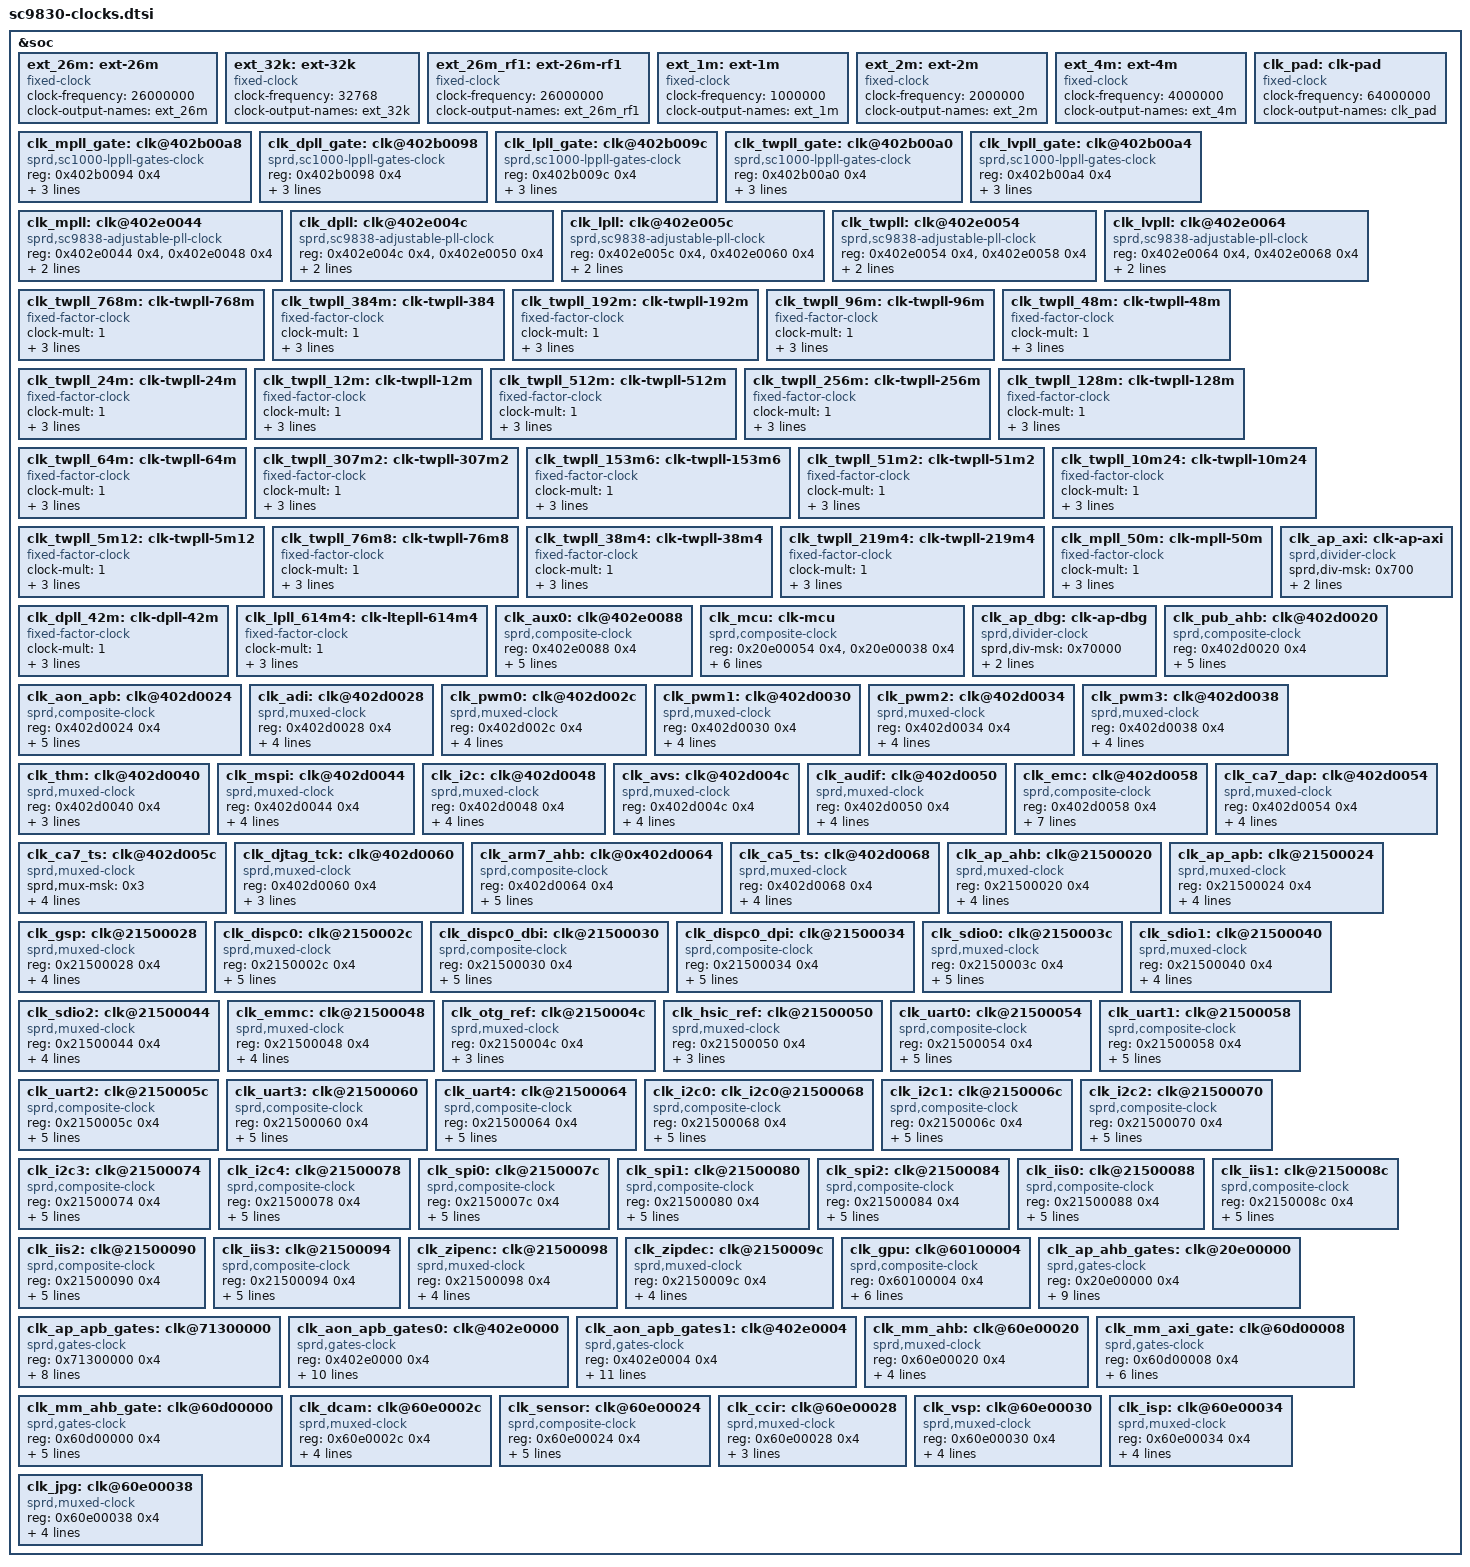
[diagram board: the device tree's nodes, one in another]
/*
 * Spreadtrum SC9830 SoC DTS file
 *
 * Copyright (C) 2015, Spreadtrum Communications Inc.
 *
 * This file is licensed under a dual GPLv2 or X11 license.
 */
&soc {
	ext_26m: ext-26m {
		compatible = "fixed-clock";
		#clock-cells = <0>;
		clock-frequency = <26000000>;
		clock-output-names = "ext_26m";
	};

	ext_32k: ext-32k {
		compatible = "fixed-clock";
		#clock-cells = <0>;
		clock-frequency = <32768>;
		clock-output-names = "ext_32k";
	};

	ext_26m_rf1: ext-26m-rf1 {
		compatible = "fixed-clock";
		#clock-cells = <0>;
		clock-frequency = <26000000>;
		clock-output-names = "ext_26m_rf1";
	};

	ext_1m: ext-1m {
		compatible = "fixed-clock";
		#clock-cells = <0>;
		clock-frequency = <1000000>;
		clock-output-names = "ext_1m";
	};

	ext_2m: ext-2m {
		compatible = "fixed-clock";
		#clock-cells = <0>;
		clock-frequency = <2000000>;
		clock-output-names = "ext_2m";
	};

	ext_4m: ext-4m {
		compatible = "fixed-clock";
		#clock-cells = <0>;
		clock-frequency = <4000000>;
		clock-output-names = "ext_4m";
	};

	clk_pad: clk-pad {
		compatible = "fixed-clock";
		#clock-cells = <0>;
		clock-frequency = <64000000>;
		clock-output-names = "clk_pad";
	};

	clk_mpll_gate: clk@402b00a8 {
		compatible = "sprd,sc1000-lppll-gates-clock";
		#clock-cells = <1>;
		reg = <0x402b0094 0x4>;
		sprd,gates-msk = <1>;
		clocks = <&ext_26m>;
		clock-output-names = "clk_mpll_gate";
	};

	clk_dpll_gate: clk@402b0098 {
		compatible = "sprd,sc1000-lppll-gates-clock";
		#clock-cells = <1>;
		reg = <0x402b0098 0x4>;
		sprd,gates-msk = <1>;
		clocks = <&ext_26m>;
		clock-output-names = "clk_dpll_gate";
	};

	clk_lpll_gate: clk@402b009c {
		compatible = "sprd,sc1000-lppll-gates-clock";
		#clock-cells = <1>;
		reg = <0x402b009c 0x4>;
		sprd,gates-msk = <1>;
		clocks = <&ext_26m>;
		clock-output-names = "clk_lpll_gate";
	};

	clk_twpll_gate: clk@402b00a0 {
		compatible = "sprd,sc1000-lppll-gates-clock";
		#clock-cells = <1>;
		reg = <0x402b00a0 0x4>;
		sprd,gates-msk = <1>;
		clocks = <&ext_26m>;
		clock-output-names = "clk_twpll_gate";
	};

	clk_lvpll_gate: clk@402b00a4 {
		compatible = "sprd,sc1000-lppll-gates-clock";
		#clock-cells = <1>;
		reg = <0x402b00a4 0x4>;
		sprd,gates-msk = <1>;
		clocks = <&ext_26m>;
		clock-output-names = "clk_lvpll_gate";
	};

	clk_mpll: clk@402e0044 {
		compatible = "sprd,sc9838-adjustable-pll-clock";
		#clock-cells = <0>;
		reg = <0x402e0044 0x4>,
		      <0x402e0048 0x4>;
		clocks = <&clk_mpll_gate 0>;
		clock-output-names = "clk_mpll";
	};

	clk_dpll: clk@402e004c {
		compatible = "sprd,sc9838-adjustable-pll-clock";
		#clock-cells = <0>;
		reg = <0x402e004c 0x4>,
		      <0x402e0050 0x4>;
		clocks = <&clk_dpll_gate 0>;
		clock-output-names = "clk_dpll";
	};

	clk_lpll: clk@402e005c {
		compatible = "sprd,sc9838-adjustable-pll-clock";
		#clock-cells = <0>;
		reg = <0x402e005c 0x4>,
		      <0x402e0060 0x4>;
		clocks = <&clk_lpll_gate 0>;
		clock-output-names = "clk_lpll";
	};

	clk_twpll: clk@402e0054 {
		compatible = "sprd,sc9838-adjustable-pll-clock";
		#clock-cells = <0>;
		reg = <0x402e0054 0x4>,
		      <0x402e0058 0x4>;
		clocks = <&clk_twpll_gate 0>;
		clock-output-names = "clk_twpll";
	};

	clk_lvpll: clk@402e0064 {
		compatible = "sprd,sc9838-adjustable-pll-clock";
		#clock-cells = <0>;
		reg = <0x402e0064 0x4>,
		      <0x402e0068 0x4>;
		clocks = <&clk_lvpll_gate 0>;
		clock-output-names = "clk_lvpll";
	};

	clk_twpll_768m: clk-twpll-768m {
		compatible = "fixed-factor-clock";
		#clock-cells = <0>;
		clock-mult = <1>;
		clock-div  = <2>;
		clocks = <&clk_twpll>;
		clock-output-names = "clk_twpll_768m";
	};

	clk_twpll_384m: clk-twpll-384 {
		compatible = "fixed-factor-clock";
		#clock-cells = <0>;
		clock-mult = <1>;
		clock-div  = <4>;
		clocks = <&clk_twpll>;
		clock-output-names = "clk_twpll_384m";
	};

	clk_twpll_192m: clk-twpll-192m {
		compatible = "fixed-factor-clock";
		#clock-cells = <0>;
		clock-mult = <1>;
		clock-div  = <8>;
		clocks = <&clk_twpll>;
		clock-output-names = "clk_twpll_192m";
	};

	clk_twpll_96m: clk-twpll-96m {
		compatible = "fixed-factor-clock";
		#clock-cells = <0>;
		clock-mult = <1>;
		clock-div  = <16>;
		clocks = <&clk_twpll>;
		clock-output-names = "clk_twpll_96m";
	};

	clk_twpll_48m: clk-twpll-48m {
		compatible = "fixed-factor-clock";
		#clock-cells = <0>;
		clock-mult = <1>;
		clock-div  = <32>;
		clocks = <&clk_twpll>;
		clock-output-names = "clk_twpll_48m";
	};

	clk_twpll_24m: clk-twpll-24m {
		compatible = "fixed-factor-clock";
		#clock-cells = <0>;
		clock-mult = <1>;
		clock-div  = <64>;
		clocks = <&clk_twpll>;
		clock-output-names = "clk_twpll_24m";
	};

	clk_twpll_12m: clk-twpll-12m {
		compatible = "fixed-factor-clock";
		#clock-cells = <0>;
		clock-mult = <1>;
		clock-div  = <128>;
		clocks = <&clk_twpll>;
		clock-output-names = "clk_twpll_12m";
	};

	clk_twpll_512m: clk-twpll-512m {
		compatible = "fixed-factor-clock";
		#clock-cells = <0>;
		clock-mult = <1>;
		clock-div  = <3>;
		clocks = <&clk_twpll>;
		clock-output-names = "clk_twpll_512m";
	};

	clk_twpll_256m: clk-twpll-256m {
		compatible = "fixed-factor-clock";
		#clock-cells = <0>;
		clock-mult = <1>;
		clock-div  = <6>;
		clocks = <&clk_twpll>;
		clock-output-names = "clk_twpll_256m";
	};

	clk_twpll_128m: clk-twpll-128m {
		compatible = "fixed-factor-clock";
		#clock-cells = <0>;
		clock-mult = <1>;
		clock-div  = <12>;
		clocks = <&clk_twpll>;
		clock-output-names = "clk_twpll_128m";
	};

	clk_twpll_64m: clk-twpll-64m {
		compatible = "fixed-factor-clock";
		#clock-cells = <0>;
		clock-mult = <1>;
		clock-div  = <24>;
		clocks = <&clk_twpll>;
		clock-output-names = "clk_twpll_64m";
	};

	clk_twpll_307m2: clk-twpll-307m2 {
		compatible = "fixed-factor-clock";
		#clock-cells = <0>;
		clock-mult = <1>;
		clock-div  = <5>;
		clocks = <&clk_twpll>;
		clock-output-names = "clk_twpll_307m2";
	};

	clk_twpll_153m6: clk-twpll-153m6 {
		compatible = "fixed-factor-clock";
		#clock-cells = <0>;
		clock-mult = <1>;
		clock-div  = <10>;
		clocks = <&clk_twpll>;
		clock-output-names = "clk_twpll_153m6";
	};

	clk_twpll_51m2: clk-twpll-51m2 {
		compatible = "fixed-factor-clock";
		#clock-cells = <0>;
		clock-mult = <1>;
		clock-div  = <30>;
		clocks = <&clk_twpll>;
		clock-output-names = "clk_twpll_51m2";
	};

	clk_twpll_10m24: clk-twpll-10m24 {
		compatible = "fixed-factor-clock";
		#clock-cells = <0>;
		clock-mult = <1>;
		clock-div  = <150>;
		clocks = <&clk_twpll>;
		clock-output-names = "clk_twpll_10m24";
	};

	clk_twpll_5m12: clk-twpll-5m12 {
		compatible = "fixed-factor-clock";
		#clock-cells = <0>;
		clock-mult = <1>;
		clock-div  = <300>;
		clocks = <&clk_twpll>;
		clock-output-names = "clk_twpll_5m12";
	};

	clk_twpll_76m8: clk-twpll-76m8 {
		compatible = "fixed-factor-clock";
		#clock-cells = <0>;
		clock-mult = <1>;
		clock-div  = <20>;
		clocks = <&clk_twpll>;
		clock-output-names = "clk_twpll_76m8";
	};

	clk_twpll_38m4: clk-twpll-38m4 {
		compatible = "fixed-factor-clock";
		#clock-cells = <0>;
		clock-mult = <1>;
		clock-div  = <40>;
		clocks = <&clk_twpll>;
		clock-output-names = "clk_twpll_38m4";
	};

	clk_twpll_219m4: clk-twpll-219m4 {
		compatible = "fixed-factor-clock";
		#clock-cells = <0>;
		clock-mult = <1>;
		clock-div  = <7>;
		clocks = <&clk_twpll>;
		clock-output-names = "clk_twpll_219m4";
	};

	clk_mpll_50m: clk-mpll-50m {
		compatible = "fixed-factor-clock";
		#clock-cells = <0>;
		clock-mult = <1>;
		clock-div = <32>;
		clocks = <&clk_mpll>;
		clock-output-names = "clk_mpll_50m";
	};

	clk_dpll_42m: clk-dpll-42m {
		compatible = "fixed-factor-clock";
		#clock-cells = <0>;
		clock-mult = <1>;
		clock-div = <32>;
		clocks = <&clk_dpll>;
		clock-output-names = "clk_dpll_42m";
	};

	clk_lpll_614m4: clk-ltepll-614m4 {
		compatible = "fixed-factor-clock";
		#clock-cells = <0>;
		clock-mult = <1>;
		clock-div = <2>;
		clocks = <&clk_lpll>;
		clock-output-names = "clk_lpll_614m4";
	};

	clk_aux0: clk@402e0088 {
		compatible = "sprd,composite-clock";
		#clock-cells = <0>;
		reg = <0x402e0088 0x4>;
		sprd,mux-msk = <0xf>;
		sprd,div-msk = <0xf0000>;
		clocks = <&ext_32k>, <&ext_26m>, <&ext_26m_rf1>,
			 <&ext_4m>, <&clk_dpll_42m>, <&clk_twpll_48m>,
			 <&clk_mpll_50m>;
		clock-output-names = "clk_aux0";
	};

	clk_mcu: clk-mcu {
		compatible = "sprd,composite-clock";
		#clock-cells = <0>;
		reg = <0x20e00054 0x4>,
		      <0x20e00038 0x4>;
		sprd,mux-msk = <0x7>;
		sprd,div-msk = <0x70>;
		clocks = <&ext_26m>, <&clk_twpll_512m>,
			 <&clk_twpll_768m>, <&clk_dpll>,
			 <&clk_lpll>, <&clk_twpll>, <&clk_mpll>;
		clock-output-names = "clk_mcu";
	};

	clk_ap_axi: clk-ap-axi {
		compatible = "sprd,divider-clock";
		#clock-cells = <0>;
		sprd,div-msk = <0x700>;
		clocks = <&clk_mcu>;
		clock-output-names = "clk_ap_axi";
	};

	clk_ap_dbg: clk-ap-dbg {
		compatible = "sprd,divider-clock";
		#clock-cells = <0>;
		sprd,div-msk = <0x70000>;
		clocks = <&clk_mcu>;
		clock-output-names = "clk_ap_dbg";
	};

	clk_pub_ahb: clk@402d0020 {
		compatible = "sprd,composite-clock";
		#clock-cells = <0>;
		reg = <0x402d0020 0x4>; /* select and divider reg */
		sprd,mux-msk = <0x3>;
		sprd,div-msk = <0x300>;
		clocks = <&ext_26m>, <&ext_4m>, <&clk_twpll_96m>,
			 <&clk_twpll_128m>;
		clock-output-names = "clk_pub_ahb";
	};

	clk_aon_apb: clk@402d0024 {
		compatible = "sprd,composite-clock";
		#clock-cells = <0>;
		reg = <0x402d0024 0x4>; /* select and divider reg */
		sprd,mux-msk = <0x3>;
		sprd,div-msk = <0x300>;
		clocks = <&ext_4m>, <&ext_26m>, <&clk_twpll_76m8>,
			 <&clk_twpll_96m>;
		clock-output-names = "clk_aon_apb";
	};

	clk_adi: clk@402d0028 {
		compatible = "sprd,muxed-clock";
		#clock-cells = <0>;
		reg = <0x402d0028 0x4>;	/* select reg */
		sprd,mux-msk = <0x3>;
		clocks = <&ext_26m>, <&ext_4m>, <&clk_twpll_38m4>,
			 <&clk_twpll_51m2>;
		clock-output-names = "clk_adi";
	};

	clk_pwm0: clk@402d002c {
		compatible = "sprd,muxed-clock";
		#clock-cells = <0>;
		reg = <0x402d002c 0x4>;	/* select reg */
		sprd,mux-msk = <0x3>;
		clocks = <&ext_32k>, <&ext_26m>, <&ext_26m_rf1>,
			 <&clk_twpll_48m>;
		clock-output-names = "clk_pwm0";
	};

	clk_pwm1: clk@402d0030 {
		compatible = "sprd,muxed-clock";
		#clock-cells = <0>;
		reg = <0x402d0030 0x4>;	/* select reg */
		sprd,mux-msk = <0x3>;
		clocks = <&ext_32k>, <&ext_26m>, <&ext_26m_rf1>,
			 <&clk_twpll_48m>;
		clock-output-names = "clk_pwm1";
	};

	clk_pwm2: clk@402d0034 {
		compatible = "sprd,muxed-clock";
		#clock-cells = <0>;
		reg = <0x402d0034 0x4>;	/* select reg */
		sprd,mux-msk = <0x3>;
		clocks = <&ext_32k>, <&ext_26m>, <&ext_26m_rf1>,
			 <&clk_twpll_48m>;
		clock-output-names = "clk_pwm2";
	};

	clk_pwm3: clk@402d0038 {
		compatible = "sprd,muxed-clock";
		#clock-cells = <0>;
		reg = <0x402d0038 0x4>;	/* select reg */
		sprd,mux-msk = <0x3>;
		clocks = <&ext_32k>, <&ext_26m>, <&ext_26m_rf1>,
			 <&clk_twpll_48m>;
		clock-output-names = "clk_pwm3";
	};

	clk_thm: clk@402d0040 {
		compatible = "sprd,muxed-clock";
		#clock-cells = <0>;
		reg = <0x402d0040 0x4>;	/* select reg */
		sprd,mux-msk = <0x1>;
		clocks = <&ext_32k>, <&ext_1m>;
		clock-output-names = "clk_thm";
	};

	clk_mspi: clk@402d0044 {
		compatible = "sprd,muxed-clock";
		#clock-cells = <0>;
		reg = <0x402d0044 0x4>;	/* select reg */
		sprd,mux-msk = <0x3>;
		clocks = <&ext_26m>, <&clk_twpll_51m2>,
			 <&clk_twpll_76m8>, <&clk_twpll_96m>;
		clock-output-names = "clk_mspi";
	};

	clk_i2c: clk@402d0048 {
		compatible = "sprd,muxed-clock";
		#clock-cells = <0>;
		reg = <0x402d0048 0x4>;	/* select reg */
		sprd,mux-msk = <0x3>;
		clocks = <&ext_26m>, <&clk_twpll_48m>,
			 <&clk_twpll_51m2>, <&clk_twpll_153m6>;
		clock-output-names = "clk_i2c";
	};

	clk_avs: clk@402d004c {
		compatible = "sprd,muxed-clock";
		#clock-cells = <0>;
		reg = <0x402d004c 0x4>;	/* select reg */
		sprd,mux-msk = <0x3>;
		clocks = <&ext_26m>, <&clk_twpll_48m>,
			 <&clk_twpll_51m2>, <&clk_twpll_96m>;
		clock-output-names = "clk_avs";
	};

	clk_audif: clk@402d0050 {
		compatible = "sprd,muxed-clock";
		#clock-cells = <0>;
		reg = <0x402d0050 0x4>;	/* select reg */
		sprd,mux-msk = <0x3>;
		clocks = <&ext_26m>, <&clk_twpll_38m4>,
			 <&clk_twpll_51m2>;
		clock-output-names = "clk_audif";
	};

	clk_emc: clk@402d0058 {
		compatible = "sprd,composite-clock";
		#clock-cells = <0>;
		reg = <0x402d0058 0x4>;
		sprd,mux-msk = <0x7>;
		sprd,div-msk = <0x700>;
		clocks = <&ext_26m>, <&clk_twpll_192m>,
			 <&clk_twpll_307m2>, <&clk_twpll_384m>,
			 <&clk_twpll_512m>, <&clk_lpll_614m4>,
			 <&clk_twpll_768m>, <&clk_dpll>;
		clock-output-names = "clk_emc";
	};

	clk_ca7_dap: clk@402d0054 {
		compatible = "sprd,muxed-clock";
		#clock-cells = <0>;
		reg = <0x402d0054 0x4>;	/* select reg */
		sprd,mux-msk = <0x3>;
		clocks = <&ext_26m>, <&clk_twpll_76m8>,
			 <&clk_twpll_128m>, <&clk_twpll_153m6>;
		clock-output-names = "clk_ca7_dap";
	};

	clk_ca7_ts: clk@402d005c {
		compatible = "sprd,muxed-clock";
		#clock-cells = <0>;
		sprd,mux-msk = <0x3>;
		reg = <0x402d005c 0x4>;	/* select reg */
		clocks = <&ext_32k>, <&ext_26m>, <&clk_twpll_128m>,
			 <&clk_twpll_153m6>;
		clock-output-names = "clk_ca7_ts";
	};

	clk_djtag_tck: clk@402d0060 {
		compatible = "sprd,muxed-clock";
		#clock-cells = <0>;
		reg = <0x402d0060 0x4>;	/* select reg */
		sprd,mux-msk = <0x1>;
		clocks = <&ext_26m>, <&ext_4m>;
		clock-output-names = "clk_djtag_tck";
	};

	clk_arm7_ahb: clk@0x402d0064 {
		compatible = "sprd,composite-clock";
		#clock-cells = <0>;
		reg = <0x402d0064 0x4>; /* select and divider reg */
		sprd,mux-msk = <0x3>;
		sprd,div-msk = <0x300>;
		clocks = <&ext_4m>, <&ext_26m>, <&clk_twpll_96m>,
			 <&clk_twpll_128m>;
		clock-output-names = "clk_arm7_ahb";
	};

	clk_ca5_ts: clk@402d0068 {
		compatible = "sprd,muxed-clock";
		#clock-cells = <0>;
		reg = <0x402d0068 0x4>; /* select reg */
		sprd,mux-msk = <0x3>;
		clocks = <&ext_32k>, <&ext_26m>, <&clk_twpll_128m>,
			 <&clk_twpll_153m6>;
		clock-output-names = "clk_ca5_ts";
	};

	clk_ap_ahb: clk@21500020 {
		compatible = "sprd,muxed-clock";
		#clock-cells = <0>;
		reg = <0x21500020 0x4>;	/* select reg */
		sprd,mux-msk = <0x3>;
		clocks = <&ext_26m>, <&clk_twpll_76m8>,
			 <&clk_twpll_128m>, <&clk_twpll_192m>;
		clock-output-names = "clk_ap_ahb";
	};

	clk_ap_apb: clk@21500024 {
		compatible = "sprd,muxed-clock";
		#clock-cells = <0>;
		reg = <0x21500024 0x4>;	/* select reg */
		sprd,mux-msk = <0x3>;
		clocks = <&ext_26m>, <&clk_twpll_64m>,
			 <&clk_twpll_96m>, <&clk_twpll_128m>;
		clock-output-names = "clk_ap_apb";
	};

	clk_gsp: clk@21500028 {
		compatible = "sprd,muxed-clock";
		#clock-cells = <0>;
		reg = <0x21500028 0x4>;	/* select reg */
		sprd,mux-msk = <0x3>;
		clocks = <&clk_twpll_96m>, <&clk_twpll_153m6>,
			 <&clk_twpll_192m>, <&clk_twpll_256m>;
		clock-output-names = "clk_gsp";
	};

	clk_dispc0: clk@2150002c {
		compatible = "sprd,muxed-clock";
		#clock-cells = <0>;
		reg = <0x2150002c 0x4>; /* select and divider reg */
		sprd,mux-msk = <0x3>;
		sprd,div-msk = <0x700>;
		clocks = <&clk_twpll_153m6>, <&clk_twpll_192m>,
			 <&clk_twpll_256m>, <&clk_twpll_307m2>;
		clock-output-names = "clk_dispc0";
	};

	clk_dispc0_dbi: clk@21500030 {
		compatible = "sprd,composite-clock";
		#clock-cells = <0>;
		reg = <0x21500030 0x4>; /* select and divider reg */
		sprd,mux-msk = <0x3>;
		sprd,div-msk = <0x700>;
		clocks = <&clk_twpll_128m>, <&clk_twpll_153m6>,
			 <&clk_twpll_192m>, <&clk_twpll_256m>;
		clock-output-names = "clk_dispc0_dbi";
	};

	clk_dispc0_dpi: clk@21500034 {
		compatible = "sprd,composite-clock";
		#clock-cells = <0>;
		reg = <0x21500034 0x4>; /* select and divider reg */
		sprd,mux-msk = <0x3>;
		sprd,div-msk = <0xff00>;
		clocks = <&clk_twpll_128m>, <&clk_twpll_153m6>,
			 <&clk_twpll_192m>, <&clk_twpll_384m>;
		clock-output-names = "clk_dispc0_dpi";
	};

	clk_sdio0: clk@2150003c {
		compatible = "sprd,muxed-clock";
		#clock-cells = <0>;
		reg = <0x2150003c 0x4>; /* select and divider reg*/
		sprd,mux-msk = <0x3>;
		sprd,div-msk = <0x700>;
		clocks = <&ext_26m>, <&clk_twpll_256m>,
			 <&clk_twpll_307m2>, <&clk_twpll_384m>;
		clock-output-names = "clk_sdio0";
	};

	clk_sdio1: clk@21500040 {
		compatible = "sprd,muxed-clock";
		#clock-cells = <0>;
		reg = <0x21500040 0x4>;	/* select reg*/
		sprd,mux-msk = <0x3>;
		clocks = <&clk_twpll_48m>, <&clk_twpll_76m8>,
			 <&clk_twpll_96m>, <&clk_twpll_128m>;
		clock-output-names = "clk_sdio1";
	};

	clk_sdio2: clk@21500044 {
		compatible = "sprd,muxed-clock";
		#clock-cells = <0>;
		reg = <0x21500044 0x4>;	/* select reg */
		sprd,mux-msk = <0x3>;
		clocks = <&clk_twpll_48m>, <&clk_twpll_76m8>,
			 <&clk_twpll_96m>, <&clk_twpll_128m>;
		clock-output-names = "clk_sdio2";
	};

	clk_emmc: clk@21500048 {
		compatible = "sprd,muxed-clock";
		#clock-cells = <0>;
		reg = <0x21500048 0x4>;	/* select reg */
		sprd,mux-msk = <0x3>;
		clocks = <&ext_26m>, <&clk_twpll_256m>,
			 <&clk_twpll_307m2>, <&clk_twpll_384m>;
		clock-output-names = "clk_emmc";
	};

	clk_otg_ref: clk@2150004c {
		compatible = "sprd,muxed-clock";
		#clock-cells = <0>;
		reg = <0x2150004c 0x4>;	/* select reg */
		sprd,mux-msk = <0x1>;
		clocks = <&clk_twpll_12m>, <&clk_twpll_24m>;
		clock-output-names = "clk_otg_ref";
	};

	clk_hsic_ref: clk@21500050 {
		compatible = "sprd,muxed-clock";
		#clock-cells = <0>;
		reg = <0x21500050 0x4>;	/* select reg */
		sprd,mux-msk = <0x1>;
		clocks = <&clk_twpll_12m>, <&clk_twpll_24m>;
		clock-output-names = "clk_hsic_ref";
	};

	clk_uart0: clk@21500054 {
		compatible = "sprd,composite-clock";
		#clock-cells = <0>;
		reg = <0x21500054 0x4>; /* select and divider reg*/
		sprd,mux-msk = <0x3>;
		sprd,div-msk = <0x700>;
		clocks = <&ext_26m>, <&clk_twpll_48m>,
			 <&clk_twpll_51m2>, <&clk_twpll_96m>;
		clock-output-names = "clk_uart0";
	};

	clk_uart1: clk@21500058 {
		compatible = "sprd,composite-clock";
		#clock-cells = <0>;
		reg = <0x21500058 0x4>; /* select and divider reg*/
		sprd,mux-msk = <0x3>;
		sprd,div-msk = <0x700>;
		clocks = <&ext_26m>, <&clk_twpll_48m>,
			 <&clk_twpll_51m2>, <&clk_twpll_96m>;
		clock-output-names = "clk_uart1";
	};

	clk_uart2: clk@2150005c {
		compatible = "sprd,composite-clock";
		#clock-cells = <0>;
		reg = <0x2150005c 0x4>; /* select and divider reg*/
		sprd,mux-msk = <0x3>;
		sprd,div-msk = <0x700>;
		clocks = <&ext_26m>, <&clk_twpll_48m>,
			 <&clk_twpll_51m2>, <&clk_twpll_96m>;
		clock-output-names = "clk_uart2";
	};

	clk_uart3: clk@21500060 {
		compatible = "sprd,composite-clock";
		#clock-cells = <0>;
		reg = <0x21500060 0x4>; /* select and divider reg*/
		sprd,mux-msk = <0x3>;
		sprd,div-msk = <0x700>;
		clocks = <&ext_26m>, <&clk_twpll_48m>,
			 <&clk_twpll_51m2>, <&clk_twpll_96m>;
		clock-output-names = "clk_uart3";
	};

	clk_uart4: clk@21500064 {
		compatible = "sprd,composite-clock";
		#clock-cells = <0>;
		reg = <0x21500064 0x4>; /* select and divider reg*/
		sprd,mux-msk = <0x3>;
		sprd,div-msk = <0x700>;
		clocks = <&ext_26m>, <&clk_twpll_48m>,
			 <&clk_twpll_51m2>, <&clk_twpll_96m>;
		clock-output-names = "clk_uart4";
	};

	clk_i2c0: clk_i2c0@21500068 {
		compatible = "sprd,composite-clock";
		#clock-cells = <0>;
		reg = <0x21500068 0x4>; /* select and divider reg*/
		sprd,mux-msk = <0x3>;
		sprd,div-msk = <0x700>;
		clocks = <&ext_26m>, <&clk_twpll_48m>,
			 <&clk_twpll_51m2>, <&clk_twpll_153m6>;
		clock-output-names = "clk_i2c0";
	};

	clk_i2c1: clk@2150006c {
		compatible = "sprd,composite-clock";
		#clock-cells = <0>;
		reg = <0x2150006c 0x4>; /* select and divider reg*/
		sprd,mux-msk = <0x3>;
		sprd,div-msk = <0x700>;
		clocks = <&ext_26m>, <&clk_twpll_48m>,
			 <&clk_twpll_51m2>, <&clk_twpll_153m6>;
		clock-output-names = "clk_i2c1";
	};

	clk_i2c2: clk@21500070 {
		compatible = "sprd,composite-clock";
		#clock-cells = <0>;
		reg = <0x21500070 0x4>; /* select and divider reg*/
		sprd,mux-msk = <0x3>;
		sprd,div-msk = <0x700>;
		clocks = <&ext_26m>, <&clk_twpll_48m>,
			 <&clk_twpll_51m2>, <&clk_twpll_153m6>;
		clock-output-names = "clk_i2c2";
	};

	clk_i2c3: clk@21500074 {
		compatible = "sprd,composite-clock";
		#clock-cells = <0>;
		reg = <0x21500074 0x4>; /* select and divider reg*/
		sprd,mux-msk = <0x3>;
		sprd,div-msk = <0x700>;
		clocks = <&ext_26m>, <&clk_twpll_48m>,
			 <&clk_twpll_51m2>, <&clk_twpll_153m6>;
		clock-output-names = "clk_i2c3";
	};

	clk_i2c4: clk@21500078 {
		compatible = "sprd,composite-clock";
		#clock-cells = <0>;
		reg = <0x21500078 0x4>; /* select and divider reg*/
		sprd,mux-msk = <0x3>;
		sprd,div-msk = <0x700>;
		clocks = <&ext_26m>, <&clk_twpll_48m>,
			 <&clk_twpll_51m2>, <&clk_twpll_153m6>;
		clock-output-names = "clk_i2c4";
	};

	clk_spi0: clk@2150007c {
		compatible = "sprd,composite-clock";
		#clock-cells = <0>;
		reg = <0x2150007c 0x4>; /* select and divider reg*/
		sprd,mux-msk = <0x3>;
		sprd,div-msk = <0x700>;
		clocks = <&ext_26m>, <&clk_twpll_96m>,
			 <&clk_twpll_153m6>, <&clk_twpll_192m>;
		clock-output-names = "clk_spi0";
	};

	clk_spi1: clk@21500080 {
		compatible = "sprd,composite-clock";
		#clock-cells = <0>;
		reg = <0x21500080 0x4>; /* select and divider reg */
		sprd,mux-msk = <0x3>;
		sprd,div-msk = <0x700>;
		clocks = <&ext_26m>, <&clk_twpll_96m>,
			 <&clk_twpll_153m6>, <&clk_twpll_192m>;
		clock-output-names = "clk_spi1";
	};

	clk_spi2: clk@21500084 {
		compatible = "sprd,composite-clock";
		#clock-cells = <0>;
		reg = <0x21500084 0x4>; /* select and divider reg*/
		sprd,mux-msk = <0x3>;
		sprd,div-msk = <0x700>;
		clocks = <&ext_26m>, <&clk_twpll_96m>,
			 <&clk_twpll_153m6>, <&clk_twpll_192m>;
		clock-output-names = "clk_spi2";
	};

	clk_iis0: clk@21500088 {
		compatible = "sprd,composite-clock";
		#clock-cells = <0>;
		reg = <0x21500088 0x4>; /* select and divider reg*/
		sprd,mux-msk = <0x3>;
		sprd,div-msk = <0x700>;
		clocks = <&ext_26m>, <&clk_twpll_128m>,
			 <&clk_twpll_153m6>;
		clock-output-names = "clk_iis0";
	};

	clk_iis1: clk@2150008c {
		compatible = "sprd,composite-clock";
		#clock-cells = <0>;
		reg = <0x2150008c 0x4>; /* select and divider reg*/
		sprd,mux-msk = <0x3>;
		sprd,div-msk = <0x700>;
		clocks = <&ext_26m>, <&clk_twpll_128m>,
			 <&clk_twpll_153m6>;
		clock-output-names = "clk_iis1";
	};

	clk_iis2: clk@21500090 {
		compatible = "sprd,composite-clock";
		#clock-cells = <0>;
		reg = <0x21500090 0x4>; /* select and divider reg*/
		sprd,mux-msk = <0x3>;
		sprd,div-msk = <0x700>;
		clocks = <&ext_26m>, <&clk_twpll_128m>,
			 <&clk_twpll_153m6>;
		clock-output-names = "clk_iis2";
	};

	clk_iis3: clk@21500094 {
		compatible = "sprd,composite-clock";
		#clock-cells = <0>;
		reg = <0x21500094 0x4>; /* select and divider reg*/
		sprd,mux-msk = <0x3>;
		sprd,div-msk = <0x700>;
		clocks = <&ext_26m>, <&clk_twpll_128m>,
			 <&clk_twpll_153m6>;
		clock-output-names = "clk_iis3";
	};

	clk_zipenc: clk@21500098 {
		compatible = "sprd,muxed-clock";
		#clock-cells = <0>;
		reg = <0x21500098 0x4>;	/* select reg */
		sprd,mux-msk = <0x3>;
		clocks = <&clk_twpll_96m>, <&clk_twpll_153m6>,
			 <&clk_twpll_192m>, <&clk_twpll_256m>;
		clock-output-names = "clk_zipenc";
	};

	clk_zipdec: clk@2150009c {
		compatible = "sprd,muxed-clock";
		#clock-cells = <0>;
		reg = <0x2150009c 0x4>;	/* select reg*/
		sprd,mux-msk = <0x3>;
		clocks = <&clk_twpll_96m>, <&clk_twpll_153m6>,
			 <&clk_twpll_192m>, <&clk_twpll_256m>;
		clock-output-names = "clk_zipdec";
	};

	clk_gpu: clk@60100004 {
		compatible = "sprd,composite-clock";
		#clock-cells = <0>;
		reg = <0x60100004 0x4>;
		sprd,mux-msk = <0x7>;
		sprd,div-msk = <0x30>;
		clocks = <&clk_twpll_153m6>, <&clk_twpll_192m>,
			<&clk_twpll_256m>, <&clk_twpll_307m2>,
			<&clk_twpll_384m>, <&clk_twpll_512m>;
		clock-output-names = "clk_gpu";
	};

	clk_ap_ahb_gates: clk@20e00000 {
		compatible = "sprd,gates-clock";
		#clock-cells = <1>;
		reg = <0x20e00000 0x4>;
		sprd,gates-msk = <0xffefff>;
		clocks = <&clk_ap_ahb>;
		clock-output-names = "dsi_eb", "dispc_eb",
					"hsic_eb", "gsp_eb",
					"otg_eb", "dma_eb",
					"nfc_eb", "drm_eb",
					"sdio0_eb", "sdio1_eb",
					"sdio2_eb", "emmc_eb",
					"spinlock_eb", "busmon0_eb",
					"busmon1_eb", "busmon2_eb",
					"nandc_eb", "nandc_2x_eb",
					"nandc_ecc_eb", "zipenc_eb",
					"zipdec_eb", "lvds_eb",
					"zipmtx_eb";
	};

	clk_ap_apb_gates: clk@71300000 {
		compatible = "sprd,gates-clock";
		#clock-cells = <1>;
		reg = <0x71300000 0x4>;
		sprd,gates-msk = <0x7fffff>;
		clocks = <&clk_ap_apb>;
		clock-output-names = "sim0_eb", "iis0_eb",
					"iis1_eb", "iis2_eb",
					"iis3_eb", "spi0_eb",
					"spi1_eb", "spi2_eb",
					"i2c0_eb", "i2c1_eb",
					"i2c2_eb", "i2c3_eb",
					"i2c4_eb", "uart0_eb",
					"uart1_eb", "uart2_eb",
					"uart3_eb", "uart4_eb",
					"ap_ckg_eb", "intc0_eb",
					"intc1_eb", "intc2_eb",
					"intc3_eb";
	};

	clk_aon_apb_gates0: clk@402e0000 {
		compatible = "sprd,gates-clock";
		#clock-cells = <1>;
		reg = <0x402e0000 0x4>;
		sprd,gates-msk = <0xffffffff>;
		clocks = <&clk_aon_apb>;
		clock-output-names = "adc_eb", "fm_eb",
					"tpc_eb", "apb_gpio_eb",
					"pwm0_eb", "pwm1_eb",
					"pwm2_eb", "pwm3_eb",
					"kpd_eb", "aon_syst_eb",
					"ap_syst_eb", "aon_tmr_eb",
					"ap_tmr0_eb", "efuse_eb",
					"eic_eb", "intc_eb",
					"adi_eb", "audif_eb",
					"aud_eb", "vbc_eb",
					"pin_eb", "ipi_eb",
					"splk_eb", "mspi_eb",
					"ap_wdg_eb", "mm_eb",
					"aon_ckg_eb", "gpu_eb",
					"apcpu_ts0_eb", "apcpu_ts1_eb",
					"dap_eb", "i2c_eb";
	};

	clk_aon_apb_gates1: clk@402e0004 {
		compatible = "sprd,gates-clock";
		#clock-cells = <1>;
		reg = <0x402e0004 0x4>;
		sprd,gates-msk = <0xfffffff>;
		clocks = <&clk_aon_apb>;
		clock-output-names = "pmu_eb", "thm_eb",
					"aux0_eb", "aux1_eb",
					"aux2_eb", "probe_eb",
					"avs_eb", "rsv2",
					"apcpu_wdg_eb", "ap_tmr1_eb",
					"ap_tmr2_eb", "disp_emc_eb",
					"zip_emc_eb", "gsp_emc_eb",
					"ca5_dap_eb", "lvds_trx_eb",
					"lvds_tcxo_eb", "mdar_eb",
					"rtc4m0_cal_eb",
					"rct4m1_cal_eb",
					"djtag_eb", "mbox_eb",
					"aon_dma_eb", "arm7_jtag_eb",
					"lvds_pll_div_en", "def_eb",
					"ca5_ts0_eb", "orp_jtag_eb";
	};

	/* MM domain */
	clk_mm_ahb: clk@60e00020 {
		compatible = "sprd,muxed-clock";
		#clock-cells = <0>;
		reg = <0x60e00020 0x4>;
		sprd,mux-msk = <0x3>;
		clocks = <&ext_26m>, <&clk_twpll_96m>, <&clk_twpll_128m>,
			<&clk_twpll_153m6>;
		clock-output-names = "clk_mm_ahb";
	};

	clk_mm_axi_gate: clk@60d00008 {
		compatible = "sprd,gates-clock";
		#clock-cells = <1>;
		reg = <0x60d00008 0x4>;
		sprd,gates-msk = <0x3ff>;
		clocks = <&clk_mm_ahb>;
		clock-output-names = "cphy_gate", "mipi_gate",
				"sensor_gate", "dcam_axi_gate",
				"isp_axi_gate", "vsp_axi_gate",
				"jpg_axi_gate", "mm_axi_gate",
				"mm_mtx_axi_gate", "vpp_axi_gate";
	};

	clk_mm_ahb_gate: clk@60d00000 {
		compatible = "sprd,gates-clock";
		#clock-cells = <1>;
		reg = <0x60d00000 0x4>;
		sprd,gates-msk = <0x1ff>;
		clocks = <&clk_mm_ahb>;
		clock-output-names = "dcam_eb", "ccir_eb",
				"isp_eb", "vsp_eb", "csi_eb",
				"jpg_eb", "ckg_eb", "mmu_eb",
				"vpp_eb";
	};

	clk_dcam: clk@60e0002c {
		compatible = "sprd,muxed-clock";
		#clock-cells = <0>;
		reg = <0x60e0002c 0x4>;
		sprd,mux-msk = <0x3>;
		clocks = <&clk_twpll_76m8>, <&clk_twpll_128m>,
			<&clk_twpll_256m>, <&clk_twpll_307m2>;
		clock-output-names = "clk_dcam";
	};

	clk_sensor: clk@60e00024 {
		compatible = "sprd,composite-clock";
		#clock-cells = <0>;
		reg = <0x60e00024 0x4>;	/* select reg and divider reg */
		clocks = <&ext_26m>, <&clk_twpll_48m>, <&clk_twpll_76m8>,
			<&clk_twpll_96m>;
		clock-output-names = "clk_sensor";
		sprd,mux-msk = <0x3>;
		sprd,div-msk = <0x700>;
	};

	clk_ccir: clk@60e00028 {
		compatible = "sprd,muxed-clock";
		#clock-cells = <0>;
		reg = <0x60e00028 0x4>;	/* select reg */
		sprd,mux-msk = <0x10000>;
		clocks = <&clk_twpll_24m>, <&clk_pad>;
		clock-output-names = "clk_ccir";
	};

	clk_vsp: clk@60e00030 {
		compatible = "sprd,muxed-clock";
		#clock-cells = <0>;
		reg = <0x60e00030 0x4>;	/* select reg */
		sprd,mux-msk = <0x3>;
		clocks = <&clk_twpll_76m8>, <&clk_twpll_128m>,
			<&clk_twpll_256m>, <&clk_twpll_307m2>;
		clock-output-names = "clk_vsp";
	};

	clk_isp: clk@60e00034 {
		compatible = "sprd,muxed-clock";
		#clock-cells = <0>;
		reg = <0x60e00034 0x4>;
		sprd,mux-msk = <0x3>;
		clocks = <&clk_twpll_76m8>, <&clk_twpll_128m>,
			<&clk_twpll_256m>, <&clk_twpll_307m2>;
		clock-output-names = "clk_isp";
	};

	clk_jpg: clk@60e00038 {
		compatible = "sprd,muxed-clock";
		#clock-cells = <0>;
		reg = <0x60e00038 0x4>;
		sprd,mux-msk = <0x3>;
		clocks = <&clk_twpll_76m8>, <&clk_twpll_128m>,
			<&clk_twpll_256m>, <&clk_twpll_307m2>;
		clock-output-names = "clk_jpg";
	};
};
